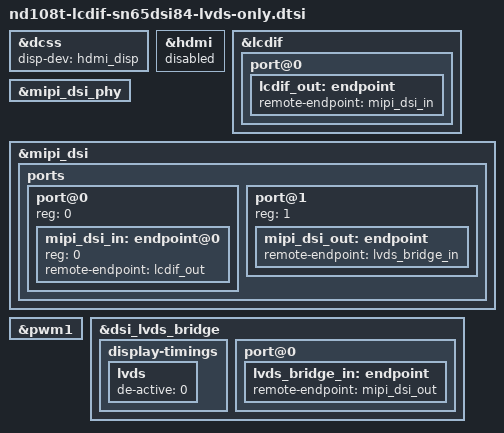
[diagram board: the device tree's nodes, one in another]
/*
 * Copyright 2018 NXP
 *
 * This program is free software; you can redistribute it and/or
 * modify it under the terms of the GNU General Public License
 * as published by the Free Software Foundation; either version 2
 * of the License, or (at your option) any later version.
 *
 * This program is distributed in the hope that it will be useful,
 * but WITHOUT ANY WARRANTY; without even the implied warranty of
 * MERCHANTABILITY or FITNESS FOR A PARTICULAR PURPOSE.  See the
 * GNU General Public License for more details.
 */

&dcss {
	status = "okay";
	disp-dev = "hdmi_disp";
};

&hdmi {
	status = "disabled";
};

&lcdif {
	status = "okay";
	port@0 {
		lcdif_out: endpoint {
			remote-endpoint = <&mipi_dsi_in>;
		};
	};
};

&mipi_dsi_phy {
	status = "okay";
};

&mipi_dsi {
	status = "okay";

	ports {
		#address-cells = <1>;
		#size-cells = <0>;

		port@0 {
			#address-cells = <1>;
			#size-cells = <0>;
			reg = <0>;
			mipi_dsi_in: endpoint@0 {
				reg = <0>;
				remote-endpoint = <&lcdif_out>;
			};
		};

		port@1 {
			reg = <1>;
			mipi_dsi_out: endpoint {
				remote-endpoint = <&lvds_bridge_in>;
			};
		};
	};
};

&pwm1 {
	status = "okay";
};

&dsi_lvds_bridge {
	status = "okay";

	display-timings {
		lvds {
			de-active = <0>;
		};
	};
	port@0 {
		lvds_bridge_in: endpoint {
			remote-endpoint = <&mipi_dsi_out>;
		};
	};
};
